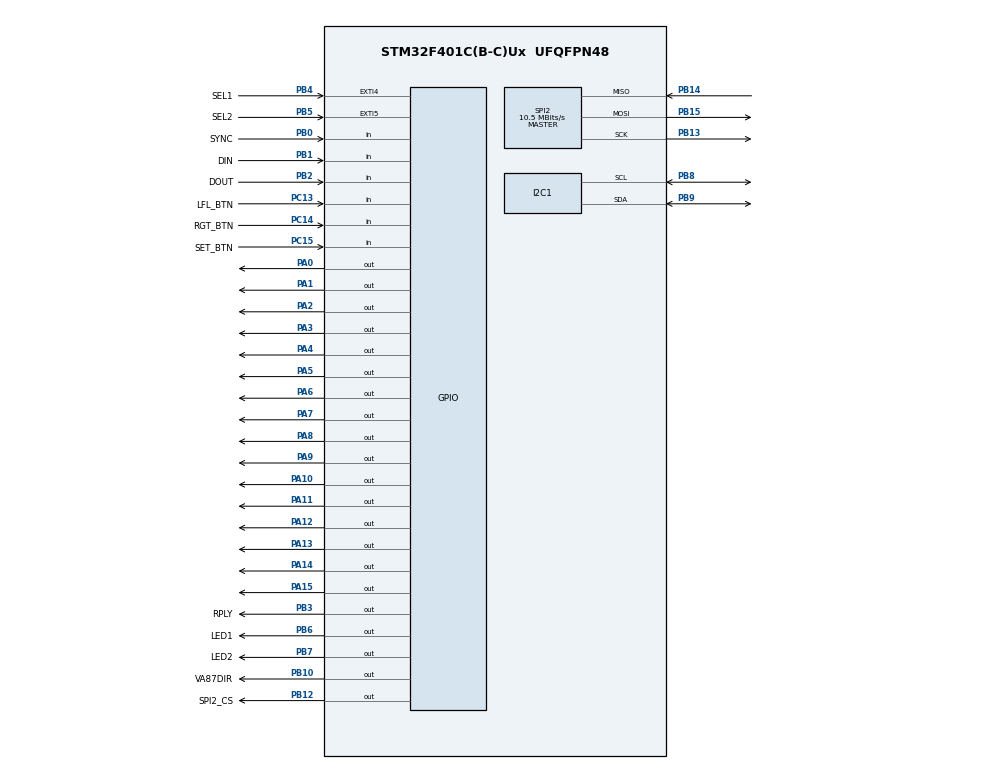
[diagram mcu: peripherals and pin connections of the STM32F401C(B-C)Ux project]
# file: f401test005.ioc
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Dma.I2C1_TX.2.Direction=DMA_MEMORY_TO_PERIPH
Dma.I2C1_TX.2.FIFOMode=DMA_FIFOMODE_DISABLE
Dma.I2C1_TX.2.Instance=DMA1_Stream6
Dma.I2C1_TX.2.MemDataAlignment=DMA_MDATAALIGN_BYTE
Dma.I2C1_TX.2.MemInc=DMA_MINC_ENABLE
Dma.I2C1_TX.2.Mode=DMA_CIRCULAR
Dma.I2C1_TX.2.PeriphDataAlignment=DMA_PDATAALIGN_BYTE
Dma.I2C1_TX.2.PeriphInc=DMA_PINC_DISABLE
Dma.I2C1_TX.2.Priority=DMA_PRIORITY_LOW
Dma.Request0=SPI2_RX
Dma.Request1=SPI2_TX
Dma.Request2=I2C1_TX
Dma.SPI2_RX.0.Direction=DMA_PERIPH_TO_MEMORY
Dma.SPI2_RX.0.FIFOMode=DMA_FIFOMODE_DISABLE
Dma.SPI2_RX.0.Instance=DMA1_Stream3
Dma.SPI2_RX.0.MemDataAlignment=DMA_MDATAALIGN_BYTE
Dma.SPI2_RX.0.MemInc=DMA_MINC_ENABLE
Dma.SPI2_RX.0.Mode=DMA_NORMAL
Dma.SPI2_RX.0.PeriphDataAlignment=DMA_PDATAALIGN_BYTE
Dma.SPI2_RX.0.PeriphInc=DMA_PINC_DISABLE
Dma.SPI2_RX.0.Priority=DMA_PRIORITY_VERY_HIGH
Dma.SPI2_TX.1.Direction=DMA_MEMORY_TO_PERIPH
Dma.SPI2_TX.1.FIFOMode=DMA_FIFOMODE_DISABLE
Dma.SPI2_TX.1.Instance=DMA1_Stream4
Dma.SPI2_TX.1.MemDataAlignment=DMA_MDATAALIGN_BYTE
Dma.SPI2_TX.1.MemInc=DMA_MINC_ENABLE
Dma.SPI2_TX.1.Mode=DMA_NORMAL
Dma.SPI2_TX.1.PeriphDataAlignment=DMA_PDATAALIGN_BYTE
Dma.SPI2_TX.1.PeriphInc=DMA_PINC_DISABLE
Dma.SPI2_TX.1.Priority=DMA_PRIORITY_VERY_HIGH
I2C1.I2C_Mode=I2C_Fast
Mcu.Family=STM32F4
Mcu.Name=STM32F401C(B-C)Ux
Mcu.Package=UFQFPN48
NVIC.DMA1_Stream3_IRQn=true\:2\:0\:true\:false\:false\:false\:false
NVIC.DMA1_Stream4_IRQn=true\:2\:0\:true\:false\:false\:false\:false
NVIC.DMA1_Stream6_IRQn=true\:6\:0\:true\:false\:false\:false\:false
NVIC.EXTI4_IRQn=true\:0\:0\:false\:false\:false\:true\:false
NVIC.EXTI9_5_IRQn=true\:0\:0\:true\:false\:false\:true\:false
NVIC.PriorityGroup=NVIC_PRIORITYGROUP_4
NVIC.TIM1_UP_TIM10_IRQn=true\:3\:0\:true\:false\:false\:true\:false
NVIC.TIM3_IRQn=true\:4\:0\:true\:false\:false\:true\:false
NVIC.TIM4_IRQn=true\:7\:0\:true\:false\:false\:true\:false
PA0-WKUP.GPIO_ModeDefaultOutputPP=GPIO_MODE_OUTPUT_OD
PA0-WKUP.GPIO_Speed=GPIO_SPEED_FREQ_VERY_HIGH
PA0-WKUP.PinState=GPIO_PIN_SET
PA0-WKUP.Signal=GPIO_Output
PA1.GPIO_ModeDefaultOutputPP=GPIO_MODE_OUTPUT_OD
PA1.GPIO_Speed=GPIO_SPEED_FREQ_VERY_HIGH
PA1.PinState=GPIO_PIN_SET
PA1.Signal=GPIO_Output
PA10.GPIO_ModeDefaultOutputPP=GPIO_MODE_OUTPUT_OD
PA10.GPIO_Speed=GPIO_SPEED_FREQ_VERY_HIGH
PA10.PinState=GPIO_PIN_SET
PA10.Signal=GPIO_Output
PA11.GPIO_ModeDefaultOutputPP=GPIO_MODE_OUTPUT_OD
PA11.GPIO_Speed=GPIO_SPEED_FREQ_VERY_HIGH
PA11.PinState=GPIO_PIN_SET
PA11.Signal=GPIO_Output
PA12.GPIO_ModeDefaultOutputPP=GPIO_MODE_OUTPUT_OD
PA12.GPIO_Speed=GPIO_SPEED_FREQ_VERY_HIGH
PA12.PinState=GPIO_PIN_SET
PA12.Signal=GPIO_Output
PA13.GPIO_ModeDefaultOutputPP=GPIO_MODE_OUTPUT_OD
PA13.GPIO_Speed=GPIO_SPEED_FREQ_VERY_HIGH
PA13.PinState=GPIO_PIN_SET
PA13.Signal=GPIO_Output
PA14.GPIO_ModeDefaultOutputPP=GPIO_MODE_OUTPUT_OD
PA14.GPIO_Speed=GPIO_SPEED_FREQ_VERY_HIGH
PA14.PinState=GPIO_PIN_SET
PA14.Signal=GPIO_Output
PA15.GPIO_ModeDefaultOutputPP=GPIO_MODE_OUTPUT_OD
PA15.GPIO_Speed=GPIO_SPEED_FREQ_VERY_HIGH
PA15.PinState=GPIO_PIN_SET
PA15.Signal=GPIO_Output
PA2.GPIO_ModeDefaultOutputPP=GPIO_MODE_OUTPUT_OD
PA2.GPIO_Speed=GPIO_SPEED_FREQ_VERY_HIGH
PA2.PinState=GPIO_PIN_SET
PA2.Signal=GPIO_Output
PA3.GPIO_ModeDefaultOutputPP=GPIO_MODE_OUTPUT_OD
PA3.GPIO_Speed=GPIO_SPEED_FREQ_VERY_HIGH
PA3.PinState=GPIO_PIN_SET
PA3.Signal=GPIO_Output
PA4.GPIO_ModeDefaultOutputPP=GPIO_MODE_OUTPUT_OD
PA4.GPIO_Speed=GPIO_SPEED_FREQ_VERY_HIGH
PA4.PinState=GPIO_PIN_SET
PA4.Signal=GPIO_Output
PA5.GPIO_ModeDefaultOutputPP=GPIO_MODE_OUTPUT_OD
PA5.GPIO_Speed=GPIO_SPEED_FREQ_VERY_HIGH
PA5.PinState=GPIO_PIN_SET
PA5.Signal=GPIO_Output
PA6.GPIO_ModeDefaultOutputPP=GPIO_MODE_OUTPUT_OD
PA6.GPIO_Speed=GPIO_SPEED_FREQ_VERY_HIGH
PA6.PinState=GPIO_PIN_SET
PA6.Signal=GPIO_Output
PA7.GPIO_ModeDefaultOutputPP=GPIO_MODE_OUTPUT_OD
PA7.GPIO_Speed=GPIO_SPEED_FREQ_VERY_HIGH
PA7.PinState=GPIO_PIN_SET
PA7.Signal=GPIO_Output
PA8.GPIO_ModeDefaultOutputPP=GPIO_MODE_OUTPUT_OD
PA8.GPIO_Speed=GPIO_SPEED_FREQ_VERY_HIGH
PA8.PinState=GPIO_PIN_SET
PA8.Signal=GPIO_Output
PA9.GPIO_ModeDefaultOutputPP=GPIO_MODE_OUTPUT_OD
PA9.GPIO_Speed=GPIO_SPEED_FREQ_VERY_HIGH
PA9.PinState=GPIO_PIN_SET
PA9.Signal=GPIO_Output
PB0.GPIO_Label=SYNC
PB0.Signal=GPIO_Input
PB1.GPIO_Label=DIN
PB1.Signal=GPIO_Input
PB10.GPIO_Label=VA87DIR
PB10.GPIO_ModeDefaultOutputPP=GPIO_MODE_OUTPUT_OD
PB10.GPIO_Speed=GPIO_SPEED_FREQ_VERY_HIGH
PB10.PinState=GPIO_PIN_SET
PB10.Signal=GPIO_Output
PB12.GPIO_Label=SPI2_CS
PB12.GPIO_PuPd=GPIO_NOPULL
PB12.GPIO_Speed=GPIO_SPEED_FREQ_VERY_HIGH
PB12.Signal=GPIO_Output
PB13.GPIO_PuPd=GPIO_PULLUP
PB13.GPIO_Speed=GPIO_SPEED_FREQ_VERY_HIGH
PB13.Mode=Full_Duplex_Master
PB13.Signal=SPI2_SCK
PB14.GPIO_PuPd=GPIO_PULLUP
PB14.GPIO_Speed=GPIO_SPEED_FREQ_VERY_HIGH
PB14.Mode=Full_Duplex_Master
PB14.Signal=SPI2_MISO
PB15.GPIO_PuPd=GPIO_PULLUP
PB15.GPIO_Speed=GPIO_SPEED_FREQ_VERY_HIGH
PB15.Mode=Full_Duplex_Master
PB15.Signal=SPI2_MOSI
PB2.GPIO_Label=DOUT
PB2.Signal=GPIO_Input
PB3.GPIO_Label=RPLY
PB3.GPIO_ModeDefaultOutputPP=GPIO_MODE_OUTPUT_OD
PB3.GPIO_Speed=GPIO_SPEED_FREQ_VERY_HIGH
PB3.PinState=GPIO_PIN_SET
PB3.Signal=GPIO_Output
PB4.GPIO_Label=SEL1
PB4.GPIO_ModeDefaultEXTI=GPIO_MODE_IT_FALLING
PB4.Signal=GPXTI4
PB5.GPIO_Label=SEL2
PB5.GPIO_ModeDefaultEXTI=GPIO_MODE_IT_FALLING
PB5.Signal=GPXTI5
PB6.GPIO_Label=LED1
PB6.GPIO_Speed=GPIO_SPEED_FREQ_VERY_HIGH
PB6.Signal=GPIO_Output
PB7.GPIO_Label=LED2
PB7.GPIO_Speed=GPIO_SPEED_FREQ_VERY_HIGH
PB7.Signal=GPIO_Output
PB8.Mode=I2C
PB8.Signal=I2C1_SCL
PB9.Mode=I2C
PB9.Signal=I2C1_SDA
PC13-ANTI_TAMP.GPIO_Label=LFL_BTN
PC13-ANTI_TAMP.GPIO_PuPd=GPIO_PULLUP
PC13-ANTI_TAMP.Signal=GPIO_Input
PC14-OSC32_IN.GPIO_Label=RGT_BTN
PC14-OSC32_IN.GPIO_PuPd=GPIO_PULLUP
PC14-OSC32_IN.Signal=GPIO_Input
PC15-OSC32_OUT.GPIO_Label=SET_BTN
PC15-OSC32_OUT.GPIO_PuPd=GPIO_PULLUP
PC15-OSC32_OUT.Signal=GPIO_Input
PH0\ -\ OSC_IN.Mode=HSE-External-Oscillator
PH0\ -\ OSC_IN.Signal=RCC_OSC_IN
PH1\ -\ OSC_OUT.Mode=HSE-External-Oscillator
PH1\ -\ OSC_OUT.Signal=RCC_OSC_OUT
ProjectManager.HeapSize=0x200
ProjectManager.StackSize=0x400
ProjectManager.TargetToolchain=STM32CubeIDE
RCC.48MHZClocksFreq_Value=84000000
RCC.AHBFreq_Value=84000000
RCC.APB1CLKDivider=RCC_HCLK_DIV2
RCC.APB1Freq_Value=42000000
RCC.APB1TimFreq_Value=84000000
RCC.APB2Freq_Value=84000000
RCC.APB2TimFreq_Value=84000000
RCC.CortexFreq_Value=84000000
RCC.HCLKFreq_Value=84000000
RCC.HSE_VALUE=25000000
RCC.HSI_VALUE=16000000
RCC.LSE_VALUE=32768
RCC.PLLM=25
RCC.PLLN=336
RCC.PLLP=RCC_PLLP_DIV4
RCC.PLLSourceVirtual=RCC_PLLSOURCE_HSE
RCC.SYSCLKFreq_VALUE=84000000
RCC.SYSCLKSource=RCC_SYSCLKSOURCE_PLLCLK
RCC.VCOOutputFreq_Value=336000000
SPI2.BaudRatePrescaler=SPI_BAUDRATEPRESCALER_4
SPI2.CalculateBaudRate=10.5 MBits/s
SPI2.Direction=SPI_DIRECTION_2LINES
SPI2.Mode=SPI_MODE_MASTER
SPI2.VirtualType=VM_MASTER
TIM10.Period=999
TIM10.Prescaler=251
TIM3.Period=5375
TIM4.Period=999
TIM4.Prescaler=8399
VP_TIM10_VS_ClockSourceINT.Mode=Enable_Timer
VP_TIM10_VS_OPM.Mode=OPM_bit
VP_TIM3_VS_ClockSourceINT.Mode=Internal
VP_TIM4_VS_ClockSourceINT.Mode=Internal
board=custom

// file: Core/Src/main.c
/* USER CODE BEGIN Header */
/**
  ******************************************************************************
  * @file           : main.c
  * @brief          : Main program body
  ******************************************************************************
  * @attention
  *
  * <h2><center>&copy; Copyright (c) 2020 STMicroelectronics.
  * All rights reserved.</center></h2>
  *
  * This software component is licensed by ST under BSD 3-Clause license,
  * the "License"; You may not use this file except in compliance with the
  * License. You may obtain a copy of the License at:
  *                        opensource.org/licenses/BSD-3-Clause
  *
  ******************************************************************************
  */
/* USER CODE END Header */
#include "main.h"
#include "dma.h"
#include "i2c.h"
#include "spi.h"
#include "tim.h"
#include "gpio.h"

/* USER CODE BEGIN Includes */
#include "ctrl128/ctrl128.h"
/* USER CODE END Includes */

void SystemClock_Config(void);

int main(void)
{

  /* MCU Configuration--------------------------------------------------------*/

  /* Reset of all peripherals, Initializes the Flash interface and the Systick. */

  LL_APB2_GRP1_EnableClock(LL_APB2_GRP1_PERIPH_SYSCFG);
  LL_APB1_GRP1_EnableClock(LL_APB1_GRP1_PERIPH_PWR);

  NVIC_SetPriorityGrouping(NVIC_PRIORITYGROUP_4);

  /* System interrupt init*/
  /* MemoryManagement_IRQn interrupt configuration */
  NVIC_SetPriority(MemoryManagement_IRQn, NVIC_EncodePriority(NVIC_GetPriorityGrouping(),8, 0));
  /* BusFault_IRQn interrupt configuration */
  NVIC_SetPriority(BusFault_IRQn, NVIC_EncodePriority(NVIC_GetPriorityGrouping(),8, 0));
  /* UsageFault_IRQn interrupt configuration */
  NVIC_SetPriority(UsageFault_IRQn, NVIC_EncodePriority(NVIC_GetPriorityGrouping(),8, 0));
  /* SVCall_IRQn interrupt configuration */
  NVIC_SetPriority(SVCall_IRQn, NVIC_EncodePriority(NVIC_GetPriorityGrouping(),8, 0));
  /* DebugMonitor_IRQn interrupt configuration */
  NVIC_SetPriority(DebugMonitor_IRQn, NVIC_EncodePriority(NVIC_GetPriorityGrouping(),8, 0));
  /* PendSV_IRQn interrupt configuration */
  NVIC_SetPriority(PendSV_IRQn, NVIC_EncodePriority(NVIC_GetPriorityGrouping(),8, 0));
  /* SysTick_IRQn interrupt configuration */
  NVIC_SetPriority(SysTick_IRQn, NVIC_EncodePriority(NVIC_GetPriorityGrouping(),8, 0));

  /* Configure the system clock */
  SystemClock_Config();

  /* Initialize all configured peripherals */
  MX_GPIO_Init();
  MX_DMA_Init();
  MX_SPI2_Init();
  MX_TIM3_Init();
  MX_TIM4_Init();
  MX_I2C1_Init();
  MX_TIM10_Init();
  /* USER CODE BEGIN 2 */
  //if((GPIOC->IDR&SET_BTN_Pin))GPIOA->MODER=0x55555555UL,GPIOA->BSRR=0xFFFF;
    ctrl128loop();
  /* USER CODE END 2 */

  /* Infinite loop */
  while (1)
  {

  }
}

void SystemClock_Config(void)
{
  LL_FLASH_SetLatency(LL_FLASH_LATENCY_2);
  while(LL_FLASH_GetLatency()!= LL_FLASH_LATENCY_2)
  {
  }
  LL_PWR_SetRegulVoltageScaling(LL_PWR_REGU_VOLTAGE_SCALE2);
  LL_RCC_HSE_Enable();

   /* Wait till HSE is ready */
  while(LL_RCC_HSE_IsReady() != 1)
  {

  }
  LL_RCC_PLL_ConfigDomain_SYS(LL_RCC_PLLSOURCE_HSE, LL_RCC_PLLM_DIV_25, 336, LL_RCC_PLLP_DIV_4);
  LL_RCC_PLL_Enable();

   /* Wait till PLL is ready */
  while(LL_RCC_PLL_IsReady() != 1)
  {

  }
  LL_RCC_SetAHBPrescaler(LL_RCC_SYSCLK_DIV_1);
  LL_RCC_SetAPB1Prescaler(LL_RCC_APB1_DIV_2);
  LL_RCC_SetAPB2Prescaler(LL_RCC_APB2_DIV_1);
  LL_RCC_SetSysClkSource(LL_RCC_SYS_CLKSOURCE_PLL);

   /* Wait till System clock is ready */
  while(LL_RCC_GetSysClkSource() != LL_RCC_SYS_CLKSOURCE_STATUS_PLL)
  {

  }
  LL_Init1msTick(84000000);
  LL_SetSystemCoreClock(84000000);
  LL_RCC_SetTIMPrescaler(LL_RCC_TIM_PRESCALER_TWICE);
}

void Error_Handler(void)
{
}

/************************ (C) COPYRIGHT STMicroelectronics *****END OF FILE****/
